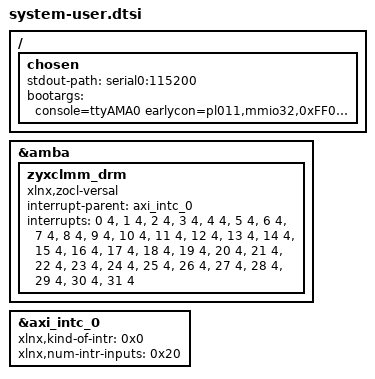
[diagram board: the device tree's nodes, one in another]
/* Copyright 2020 Xilinx Inc.
# 
# Licensed under the Apache License, Version 2.0 (the "License");
# you may not use this file except in compliance with the License.
# You may obtain a copy of the License at
#
#     http://www.apache.org/licenses/LICENSE-2.0
#
# Unless required by applicable law or agreed to in writing, software
# distributed under the License is distributed on an "AS IS" BASIS,
# WITHOUT WARRANTIES OR CONDITIONS OF ANY KIND, either express or implied.
# See the License for the specific language governing permissions and
# limitations under the License.
*/

/include/ "system-conf.dtsi"
/ {
	chosen {
		stdout-path = "serial0:115200";
        bootargs = "console=ttyAMA0 earlycon=pl011,mmio32,0xFF000000,115200n8 clk_ignore_unused root=/dev/mmcblk1p2 rw rootwait rootfs=ext4";
	};
};

&amba {
    zyxclmm_drm {
        compatible = "xlnx,zocl-versal";
        status = "okay";
        interrupt-parent = <&axi_intc_0>;
        interrupts = <0  4>, <1  4>, <2  4>, <3  4>,
                 <4  4>, <5  4>, <6  4>, <7  4>,
                 <8  4>, <9  4>, <10 4>, <11 4>,
                 <12 4>, <13 4>, <14 4>, <15 4>,
                 <16 4>, <17 4>, <18 4>, <19 4>,
                 <20 4>, <21 4>, <22 4>, <23 4>,
                 <24 4>, <25 4>, <26 4>, <27 4>,
                 <28 4>, <29 4>, <30 4>, <31 4>;
    };
};

&axi_intc_0 {
      xlnx,kind-of-intr = <0x0>;
      xlnx,num-intr-inputs = <0x20>;
};
